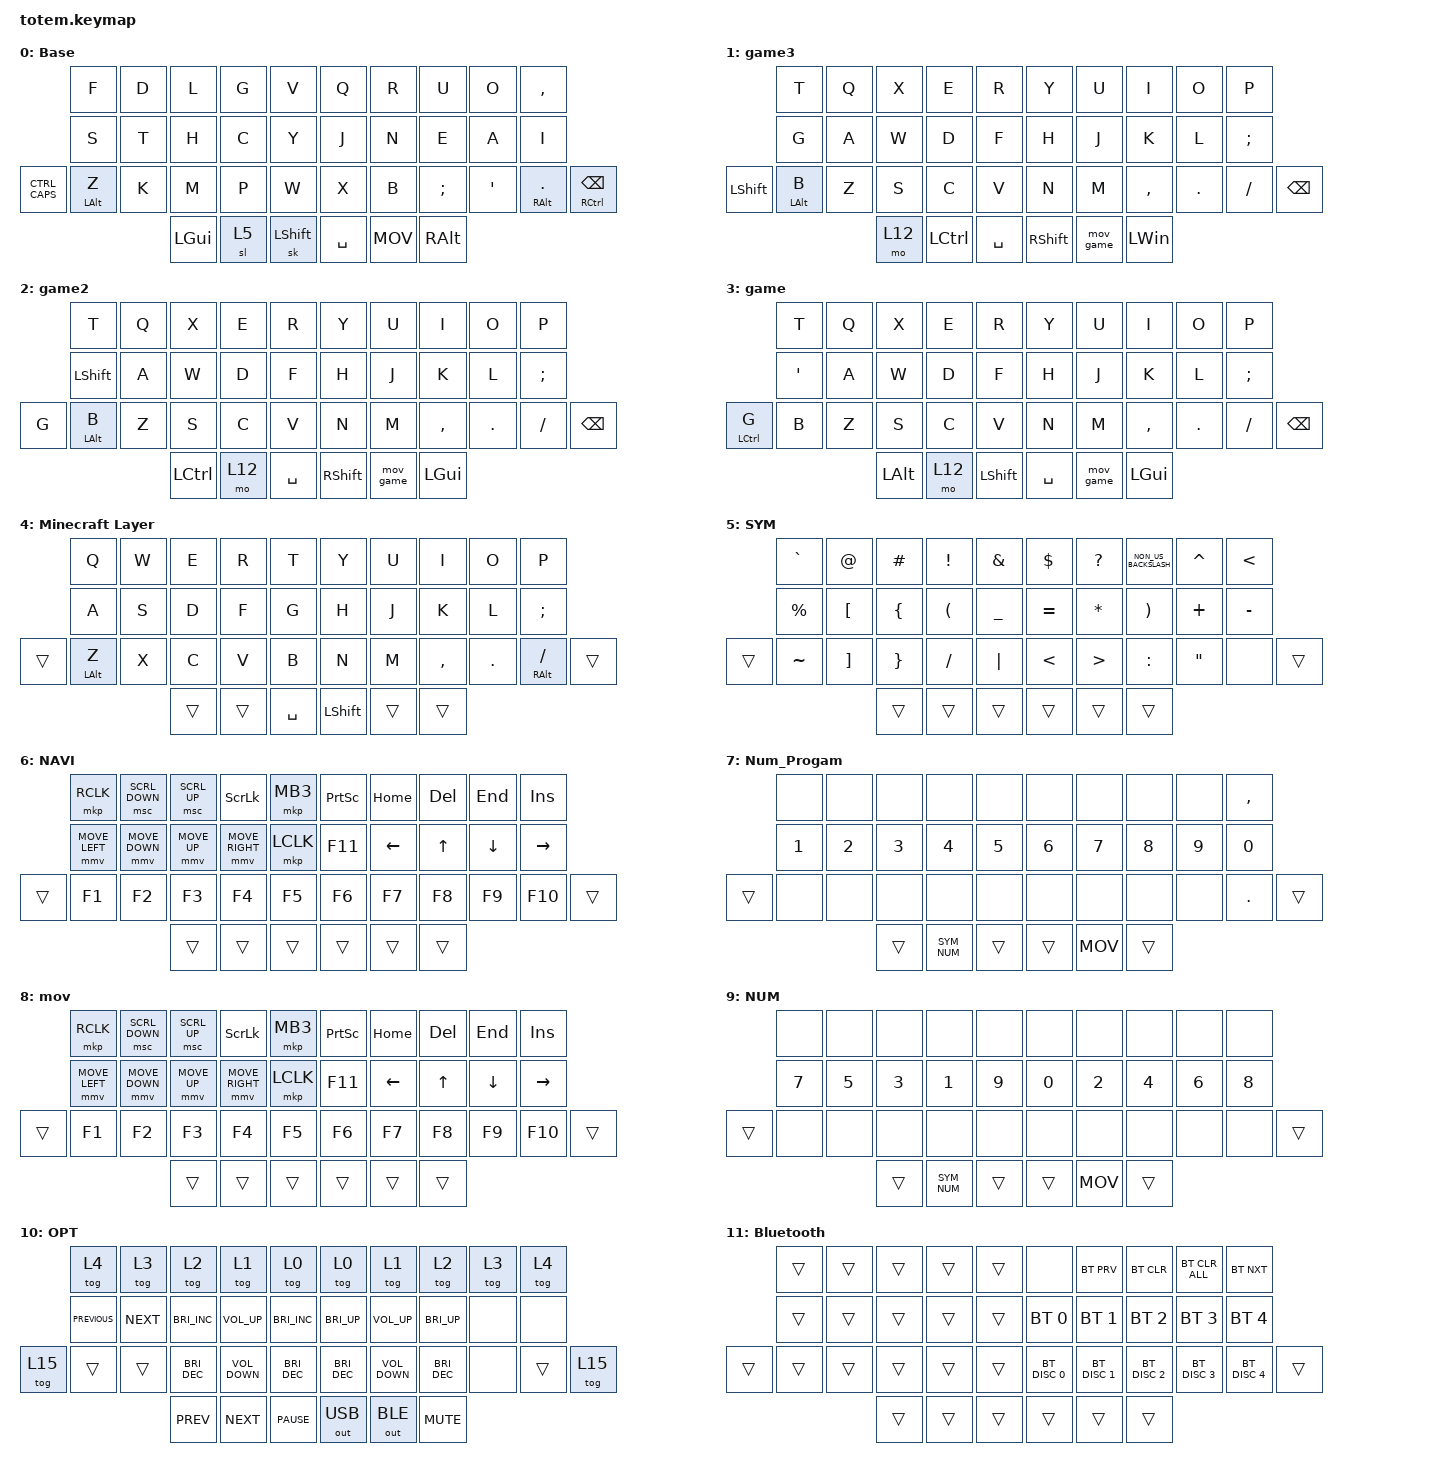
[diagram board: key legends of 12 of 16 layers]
//
//                                                        ▀▀▀▀▀     ▀▀▀▀▀          ▀▀█▀▀
//                                                        ▄▀▀▀▄  ▄  ▄▀▀▀▄  ▄  ▄▀▀▀▄  █  ▄▀▀▀▄
//                                                        █   █  █  █   █  █  █   █  █  █   █
//                                                         ▀▀▀   █   ▀▀▀   █   ▀▀▀   ▀   ▀▀▀
//                                                               █      ▄▄▄█▄▄▄    █   █  
//                                                               ▀      █  █  █     █▄█
//                                                             ▀▀▀▀▀    █  █  █      ▀
//                                                                      ▀  ▀  ▀
//
// ▄▄▄▄▄▄▄▄▄▄▄▄▄▄▄▄▄▄▄▄▄▄▄▄▄▄▄▄▄▄▄▄▄▄▄▄▄▄▄▄▄▄▄▄▄▄▄▄▄▄▄▄▄▄▄▄▄▄▄▄▄▄▄▄▄▄▄▄▄▄▄▄▄▄▄▄▄▄▄▄▄▄▄▄▄▄▄▄▄▄▄▄▄▄▄▄▄▄▄▄▄▄▄▄▄▄▄▄▄▄▄▄▄▄▄▄▄▄▄▄▄▄▄▄▄▄▄▄▄▄▄▄▄▄▄▄▄▄▄▄▄▄▄▄▄▄▄▄▄

#include <behaviors/mouse_keys.dtsi>
#include <dt-bindings/zmk/mouse.h>
#include <behaviors.dtsi>
#include <dt-bindings/zmk/bt.h>
#include <dt-bindings/zmk/keys.h>
#include <dt-bindings/zmk/outputs.h>
#include <dt-bindings/zmk/pointing.h>

#define ZMK_POINTING_DEFAULT_MOVE_VAL 4000 // default: 600
#define ZMK_POINTING_DEFAULT_SCRL_VAL 15    // default: 10
#define BASE 0
#define NAV  1
#define SYM  2
#define ADJ  3

&mt {
    quick-tap-ms = <100>;
    global-quick-tap;
    flavor = "tap-preferred";
    tapping-term-ms = <250>;
};

&sk {
    quick-release;
    release-after-ms = <350>;
};

&soft_off {
    hold-time-ms = <2000>; // Only turn off it the key is held for 3 seconds or longer.
};

&sl { release-after-ms = <350>; };

/ {
    combos {
        compatible = "zmk,combos";

        esc {
            timeout-ms = <30>;
            key-positions = <2 1>;
            bindings = <&kp ESC>;
            layers = <1 4 8 6 4 0 8 2 3>;
        };

        enter {
            bindings = <&kp ENTER>;
            key-positions = <16 17 18>;
            timeout-ms = <30>;
            layers = <1 4 8 6 0 4 8 2 3>;
        };

        tab {
            bindings = <&kp TAB>;
            key-positions = <13 12>;
            timeout-ms = <30>;
            layers = <4 8 6 0 4 8>;
        };

        option {
            bindings = <&mo 10>;
            key-positions = <22 23 21>;
            timeout-ms = <30>;
            layers = <1 4 0 4 8 2 3>;
        };

        Bluetooth {
            bindings = <&mo 11>;
            key-positions = <2 3 1>;
            timeout-ms = <100>;
            layers = <1 4 0 4 2 3>;
        };

        Option_2 {
            bindings = <&mo 10>;
            key-positions = <29 28 30>;
            timeout-ms = <30>;
            layers = <1 4 0 4 2 3>;
        };

        Reset_Button {
            bindings = <&kp LC(RA(K))>;
            key-positions = <20 31 35 34>;
            timeout-ms = <50>;
            layers = <1 4 0 4 2 3>;
        };

        tabgaming {
            bindings = <&kp TAB>;
            key-positions = <3 2>;
            timeout-ms = <30>;
            layers = <1 3 2>;
        };
    };

    behaviors {
        CTRL_CAPS: CTRL_CAPS {
            compatible = "zmk,behavior-tap-dance";
            label = "CTRL_CAPS";
            #binding-cells = <0>;
            bindings = <&kp LEFT_CONTROL>, <&kp CAPSLOCK>;

            tapping-term-ms = <250>;
        };

        Pressy_Layer: Pressy_Layer {
            compatible = "zmk,behavior-tap-dance";
            label = "PRESSY_LAYER";
            #binding-cells = <0>;
            bindings = <&none>, <&none>, <&tog 15>;

            tapping-term-ms = <250>;
        };

        SYM_NUM: SYM_NUM {
            compatible = "zmk,behavior-tap-dance";
            label = "SYM_NUM";
            #binding-cells = <0>;
            bindings = <&sl 5>, <&sl 9>;

            tapping-term-ms = <250>;
        };

        MOV: MOV {
            compatible = "zmk,behavior-tap-dance";
            label = "MOV";
            #binding-cells = <0>;
            bindings = <&mo 6>, <&tog 6>;

            tapping-term-ms = <300>;
        };

        Backspace1: Backspace1 {
            compatible = "zmk,behavior-tap-dance";
            label = "BACKSPACE1";
            #binding-cells = <0>;
            bindings = <&kp BACKSPACE>;
            tapping-term-ms = <450>;
        };

        mov_game: mov_game {
            compatible = "zmk,behavior-tap-dance";
            label = "MOV_GAME";
            #binding-cells = <0>;
            bindings = <&mo 5>, <&mo 6>;

            tapping-term-ms = <300>;
        };

        Backspace_N_Ctrl: Backspace_N_Ctrl {
            compatible = "zmk,behavior-hold-tap";
            label = "BACKSPACE_N_CTRL";
            bindings = <&kp>, <&kp>;

            #binding-cells = <2>;
            tapping-term-ms = <400>;
            flavor = "tap-preferred";
        };

        Left_ALT: Left_ALT {
            compatible = "zmk,behavior-hold-tap";
            label = "LEFT_ALT";
            bindings = <&kp>, <&kp>;

            #binding-cells = <2>;
            flavor = "tap-preferred";
            tapping-term-ms = <400>;
        };

        Right_ALT: Right_ALT {
            compatible = "zmk,behavior-hold-tap";
            label = "RIGHT_ALT";
            bindings = <&kp>, <&kp>;

            #binding-cells = <2>;
            tapping-term-ms = <500>;
            flavor = "tap-preferred";
        };

        new_behavior: new_behavior {
            compatible = "zmk,behavior-hold-tap";
            label = "NEW_BEHAVIOR";
            bindings = <&kp>, <&kp>;

            #binding-cells = <2>;
            flavor = "tap-preferred";
            tapping-term-ms = <500>;
        };
    };

    behaviors {
    };

    behaviors {
    };

    keymap {
        compatible = "zmk,keymap";

        // ▄▄▄▄▄▄▄▄▄▄▄▄▄▄▄▄▄▄▄▄▄▄▄▄▄▄▄▄▄▄▄▄▄▄▄▄▄▄▄▄▄▄▄▄▄▄▄▄▄▄▄▄▄▄▄▄▄▄▄▄▄▄▄▄▄▄▄▄▄▄▄▄▄▄▄▄▄▄▄▄▄▄▄▄▄▄▄▄▄▄▄▄▄▄▄▄▄▄▄▄▄▄▄▄▄▄▄▄▄▄▄▄▄▄▄▄▄▄▄▄▄▄▄▄▄▄▄▄▄▄▄▄▄▄▄▄▄▄▄▄▄▄▄▄▄▄▄▄▄

        Rain {
            label = "Base";
            bindings = <
            &kp F                 &kp D  &kp L         &kp G  &kp V             &kp Q      &kp R  &kp U          &kp O    &kp COMMA
            &kp S                 &kp T  &kp H         &kp C  &kp Y             &kp J      &kp N  &kp E          &kp A    &kp I
&CTRL_CAPS  &Left_ALT LEFT_ALT Z  &kp K  &kp M         &kp P  &kp W             &kp X      &kp B  &kp SEMI       &kp SQT  &Right_ALT RIGHT_ALT PERIOD  &Backspace_N_Ctrl RIGHT_CONTROL BACKSPACE
                                         &kp LEFT_GUI  &sl 5  &sk LEFT_SHIFT    &kp SPACE  &MOV   &kp RIGHT_ALT
            >;
        };

        Gaming_Volley {
            label = "game3";
            bindings = <
                &kp T           &kp Q  &kp X   &kp E             &kp R        &kp Y            &kp U      &kp I         &kp O    &kp P
                &kp G           &kp A  &kp W   &kp D             &kp F        &kp H            &kp J      &kp K         &kp L    &kp SEMI
&kp LEFT_SHIFT  &mt LEFT_ALT B  &kp Z  &kp S   &kp C             &kp V        &kp N            &kp M      &kp COMMA     &kp DOT  &kp FSLH  &kp BACKSPACE
                                       &mo 12  &kp LEFT_CONTROL  &kp SPACE    &kp RIGHT_SHIFT  &mov_game  &kp LEFT_WIN
            >;
        };

        Gaming2 {
            label = "game2";
            bindings = <
       &kp T           &kp Q  &kp X      &kp E   &kp R        &kp Y            &kp U      &kp I         &kp O    &kp P
       &kp LEFT_SHIFT  &kp A  &kp W      &kp D   &kp F        &kp H            &kp J      &kp K         &kp L    &kp SEMI
&kp G  &mt LEFT_ALT B  &kp Z  &kp S      &kp C   &kp V        &kp N            &kp M      &kp COMMA     &kp DOT  &kp FSLH  &kp BACKSPACE
                              &kp LCTRL  &mo 12  &kp SPACE    &kp RIGHT_SHIFT  &mov_game  &kp LEFT_GUI
            >;
        };

        Gaming {
            label = "game";
            bindings = <
                    &kp T     &kp Q  &kp X         &kp E   &kp R             &kp Y      &kp U      &kp I         &kp O    &kp P
                    &kp APOS  &kp A  &kp W         &kp D   &kp F             &kp H      &kp J      &kp K         &kp L    &kp SEMI
&mt LEFT_CONTROL G  &kp B     &kp Z  &kp S         &kp C   &kp V             &kp N      &kp M      &kp COMMA     &kp DOT  &kp FSLH  &kp BACKSPACE
                                     &kp LEFT_ALT  &mo 12  &kp LEFT_SHIFT    &kp SPACE  &mov_game  &kp LEFT_GUI
            >;
        };

        Minecraft {
            label = "Minecraft Layer";
            bindings = <
        &kp Q                 &kp W  &kp E   &kp R   &kp T        &kp Y           &kp U   &kp I      &kp O    &kp P
        &kp A                 &kp S  &kp D   &kp F   &kp G        &kp H           &kp J   &kp K      &kp L    &kp SEMI
&trans  &Left_ALT LEFT_ALT Z  &kp X  &kp C   &kp V   &kp B        &kp N           &kp M   &kp COMMA  &kp DOT  &Right_ALT RIGHT_ALT SLASH  &trans
                                     &trans  &trans  &kp SPACE    &kp LEFT_SHIFT  &trans  &trans
            >;
        };

        Special_Characters {
            label = "SYM";
            bindings = <
        &kp GRAVE    &kp AT_SIGN        &kp HASH         &kp EXCLAMATION       &kp AMPERSAND     &kp DOLLAR     &kp QUESTION      &kp NON_US_BACKSLASH   &kp CARET          &kp LESS_THAN
        &kp PERCENT  &kp LEFT_BRACKET   &kp LEFT_BRACE   &kp LEFT_PARENTHESIS  &kp UNDERSCORE    &kp EQUAL      &kp ASTERISK      &kp RIGHT_PARENTHESIS  &kp PLUS           &kp MINUS
&trans  &kp TILDE    &kp RIGHT_BRACKET  &kp RIGHT_BRACE  &kp SLASH             &kp PIPE          &kp LESS_THAN  &kp GREATER_THAN  &kp COLON              &kp DOUBLE_QUOTES  &none          &trans
                                        &trans           &trans                &trans            &trans         &trans            &trans
            >;
        };

        Movement {
            // ┏━━━━━━━━━━━━━━━━━━━━━━━━━━━━━━━━━━━━━━━┓

            label = "NAVI";

            // ┗━━━━━━━━━━━━━━━━━━━━━━━━━━━━━━━━━━━━━━━┛
            //             ┏━━━━━━━━━━━┳━━━━━━━━━━━┳━━━━━━━━━━━┳━━━━━━━━━━━┳━━━━━━━━━━━┓   ┏━━━━━━━━━━━┳━━━━━━━━━━━┳━━━━━━━━━━━┳━━━━━━━━━━━┳━━━━━━━━━━━┓
            //             ┃     !     ┃     @     ┃     #     ┃     $     ┃     %     ┃   ┃     ˆ     ┃     &     ┃     Ü     ┃     '     ┃     "     ┃
            //             ┣━━━━━━━━━━━╋━━━━━━━━━━━╋━━━━━━━━━━━╋━━━━━━━━━━━╋━━━━━━━━━━━┫   ┣━━━━━━━━━━━╋━━━━━━━━━━━╋━━━━━━━━━━━╋━━━━━━━━━━━╋━━━━━━━━━━━┫
            //             ┃     Ä     ┃           ┃    SZ     ┃           ┃           ┃   ┃   MUTE    ┃   YEN     ┃   EURO    ┃  POUND    ┃     Ö     ┃
            // ┏━━━━━━━━━━━╋━━━━━━━━━━━╋━━━━━━━━━━━╋━━━━━━━━━━━╋━━━━━━━━━━━╋━━━━━━━━━━━┫   ┣━━━━━━━━━━━╋━━━━━━━━━━━╋━━━━━━━━━━━╋━━━━━━━━━━━╋━━━━━━━━━━━╋━━━━━━━━━━━┓
            // ┃           ┃  EMAIL1   ┃  EMAIL2   ┃           ┃           ┃           ┃   ┃   VOL-    ┃   VOL+    ┃   LAST    ┃   NEXT    ┃     \     ┃           ┃
            // ┗━━━━━━━━━━━┻━━━━━━━━━━━┻━━━━━━━━━━━╋━━━━━━━━━━━╋━━━━━━━━━━━╋━━━━━━━━━━━┫   ┣━━━━━━━━━━━╋━━━━━━━━━━━╋━━━━━━━━━━━╋━━━━━━━━━━━┻━━━━━━━━━━━┻━━━━━━━━━━━┛
            //                                     ┃           ┃    GIF    ┃    ADJ    ┃   ┃           ┃           ┃           ┃
            //                                     ┗━━━━━━━━━━━┻━━━━━━━━━━━┻━━━━━━━━━━━┛   ┗━━━━━━━━━━━┻━━━━━━━━━━━┻━━━━━━━━━━━┛

            bindings = <
        &mkp RCLK       &msc SCRL_DOWN  &msc SCRL_UP  &kp SLCK         &mkp MB3     &kp PRINTSCREEN  &kp HOME        &kp DEL       &kp END   &kp INSERT
        &mmv MOVE_LEFT  &mmv MOVE_DOWN  &mmv MOVE_UP  &mmv MOVE_RIGHT  &mkp LCLK    &kp F11          &kp LEFT_ARROW  &kp UP_ARROW  &kp DOWN  &kp RIGHT
&trans  &kp F1          &kp F2          &kp F3        &kp F4           &kp F5       &kp F6           &kp F7          &kp F8        &kp F9    &kp F10     &trans
                                        &trans        &trans           &trans       &trans           &trans          &trans
            >;
        };

        Num_Progam {
            bindings = <
        &none   &none   &none   &none     &none     &none   &none   &none   &none   &kp COMMA
        &kp N1  &kp N2  &kp N3  &kp N4    &kp N5    &kp N6  &kp N7  &kp N8  &kp N9  &kp N0
&trans  &none   &none   &none   &none     &none     &none   &none   &none   &none   &kp PERIOD  &trans
                        &trans  &SYM_NUM  &trans    &trans  &MOV    &trans
            >;
        };

        mov {
            label = "mov";
            bindings = <
        &mkp RCLK       &msc SCRL_DOWN  &msc SCRL_UP  &kp SLCK         &mkp MB3     &kp PRINTSCREEN  &kp HOME        &kp DEL       &kp END   &kp INSERT
        &mmv MOVE_LEFT  &mmv MOVE_DOWN  &mmv MOVE_UP  &mmv MOVE_RIGHT  &mkp LCLK    &kp F11          &kp LEFT_ARROW  &kp UP_ARROW  &kp DOWN  &kp RIGHT
&trans  &kp F1          &kp F2          &kp F3        &kp F4           &kp F5       &kp F6           &kp F7          &kp F8        &kp F9    &kp F10     &trans
                                        &trans        &trans           &trans       &trans           &trans          &trans
            >;
        };

        NUM {
            bindings = <
        &none   &none   &none   &none     &none     &none   &none   &none   &none   &none
        &kp N7  &kp N5  &kp N3  &kp N1    &kp N9    &kp N0  &kp N2  &kp N4  &kp N6  &kp N8
&trans  &none   &none   &none   &none     &none     &none   &none   &none   &none   &none   &trans
                        &trans  &SYM_NUM  &trans    &trans  &MOV    &trans
            >;
        };

        Option {
            // ┏━━━━━━━━━━━━━━━━━━━━━━━━━━━━━━━━━━━━━━━┓

            label = "OPT";

            // ┗━━━━━━━━━━━━━━━━━━━━━━━━━━━━━━━━━━━━━━━┛
            //             ┏━━━━━━━━━━━┳━━━━━━━━━━━┳━━━━━━━━━━━┳━━━━━━━━━━━┳━━━━━━━━━━━┓   ┏━━━━━━━━━━━┳━━━━━━━━━━━┳━━━━━━━━━━━┳━━━━━━━━━━━┳━━━━━━━━━━━┓
            //             ┃   RESET   ┃ BT CLEAR  ┃  OUT TOG  ┃           ┃           ┃   ┃           ┃    F7     ┃    F8     ┃    F9     ┃    F12    ┃
            //             ┣━━━━━━━━━━━╋━━━━━━━━━━━╋━━━━━━━━━━━╋━━━━━━━━━━━╋━━━━━━━━━━━┫   ┣━━━━━━━━━━━╋━━━━━━━━━━━╋━━━━━━━━━━━╋━━━━━━━━━━━╋━━━━━━━━━━━┫
            //             ┃ BOOTLOAD  ┃ BT NEXT   ┃           ┃           ┃           ┃   ┃           ┃    F4     ┃    F5     ┃    F6     ┃    F11    ┃
            // ┏━━━━━━━━━━━╋━━━━━━━━━━━╋━━━━━━━━━━━╋━━━━━━━━━━━╋━━━━━━━━━━━╋━━━━━━━━━━━┫   ┣━━━━━━━━━━━╋━━━━━━━━━━━╋━━━━━━━━━━━╋━━━━━━━━━━━╋━━━━━━━━━━━╋━━━━━━━━━━━┓
            // ┃           ┃           ┃ BT PREV   ┃           ┃           ┃           ┃   ┃           ┃    F1     ┃    F2     ┃    F3     ┃    F10    ┃           ┃
            // ┗━━━━━━━━━━━┻━━━━━━━━━━━┻━━━━━━━━━━━╋━━━━━━━━━━━╋━━━━━━━━━━━╋━━━━━━━━━━━┫   ┣━━━━━━━━━━━╋━━━━━━━━━━━╋━━━━━━━━━━━╋━━━━━━━━━━━┻━━━━━━━━━━━┻━━━━━━━━━━━┛
            //                                     ┃           ┃           ┃           ┃   ┃           ┃           ┃           ┃
            //                                     ┗━━━━━━━━━━━┻━━━━━━━━━━━┻━━━━━━━━━━━┛   ┗━━━━━━━━━━━┻━━━━━━━━━━━┻━━━━━━━━━━━┛

            bindings = <
         &tog 4          &tog 3      &tog 2                &tog 1             &tog 0                  &tog 0         &tog 1             &tog 2         &tog 3  &tog 4
         &kp C_PREVIOUS  &kp C_NEXT  &kp C_BRIGHTNESS_INC  &kp C_VOLUME_UP    &kp C_BRIGHTNESS_INC    &kp C_BRI_UP   &kp C_VOLUME_UP    &kp C_BRI_UP   &none   &none
&tog 15  &trans          &trans      &kp C_BRIGHTNESS_DEC  &kp C_VOLUME_DOWN  &kp C_BRIGHTNESS_DEC    &kp C_BRI_DEC  &kp C_VOLUME_DOWN  &kp C_BRI_DEC  &none   &trans  &tog 15
                                     &kp C_PREV            &kp C_NEXT         &kp C_PAUSE             &out OUT_USB   &out OUT_BLE       &kp C_MUTE
            >;
        };

        Bluetooth {
            bindings = <
        &trans  &trans  &trans  &trans  &trans    &none          &bt BT_PRV     &bt BT_CLR     &bt BT_CLR_ALL  &bt BT_NXT
        &trans  &trans  &trans  &trans  &trans    &bt BT_SEL 0   &bt BT_SEL 1   &bt BT_SEL 2   &bt BT_SEL 3    &bt BT_SEL 4
&trans  &trans  &trans  &trans  &trans  &trans    &bt BT_DISC 0  &bt BT_DISC 1  &bt BT_DISC 2  &bt BT_DISC 3   &bt BT_DISC 4  &trans
                        &trans  &trans  &trans    &trans         &trans         &trans
            >;
        };

        Num_Gaming {
            bindings = <
        &kp N1  &kp N2  &kp N3  &kp N4  &kp N5    &none   &none   &none   &none  &none
        &none   &none   &none   &none   &none     &none   &none   &none   &none  &none
&trans  &kp N6  &kp N7  &kp N8  &kp N9  &kp N0    &none   &none   &none   &none  &none  &trans
                        &trans  &trans  &trans    &trans  &trans  &trans
            >;
        };

        mov2 {
            label = "mov2";
            bindings = <
        &mkp RCLK       &msc SCRL_DOWN  &msc SCRL_UP  &kp SLCK         &mkp MB3     &kp PRINTSCREEN  &kp HOME        &kp DEL       &kp END   &kp INSERT
        &mmv MOVE_LEFT  &mmv MOVE_DOWN  &mmv MOVE_UP  &mmv MOVE_RIGHT  &mkp LCLK    &kp F11          &kp LEFT_ARROW  &kp UP_ARROW  &kp DOWN  &kp RIGHT
&trans  &kp F1          &kp F2          &kp F3        &kp F4           &kp F5       &kp F6           &kp F7          &kp F8        &kp F9    &kp F10     &trans
                                        &trans        &trans           &trans       &trans           &trans          &trans
            >;
        };

        Number {
            bindings = <
        &none  &none  &none   &none   &none     &none   &kp N7  &kp N8  &kp N9  &none
        &none  &none  &none   &none   &none     &none   &kp N4  &kp N5  &kp N6  &none
&trans  &none  &none  &none   &none   &none     &none   &kp N1  &kp N2  &kp N3  &none  &trans
                      &trans  &trans  &trans    &trans  &kp N0  &trans
            >;
        };

        None_Layer {
            bindings = <
       &none  &none  &none          &none  &none    &none  &none  &none  &none  &none
       &none  &none  &none          &none  &none    &none  &none  &none  &none  &none
&none  &none  &none  &none          &none  &none    &none  &none  &none  &none  &none  &none
                     &Pressy_Layer  &none  &none    &none  &none  &none
            >;
        };
    };

    conditional_layers {
        compatible = "zmk,conditional-layers";

        num {
            if-layers = <5 6>;
            then-layer = <7>;
        };

        num2 {
            if-layers = <6 5>;
            then-layer = <7>;
        };

        mov_game {
            if-layers = <12 5>;
            then-layer = <13>;
        };

        move2_game {
            if-layers = <5 12>;
            then-layer = <13>;
        };
    };
};
